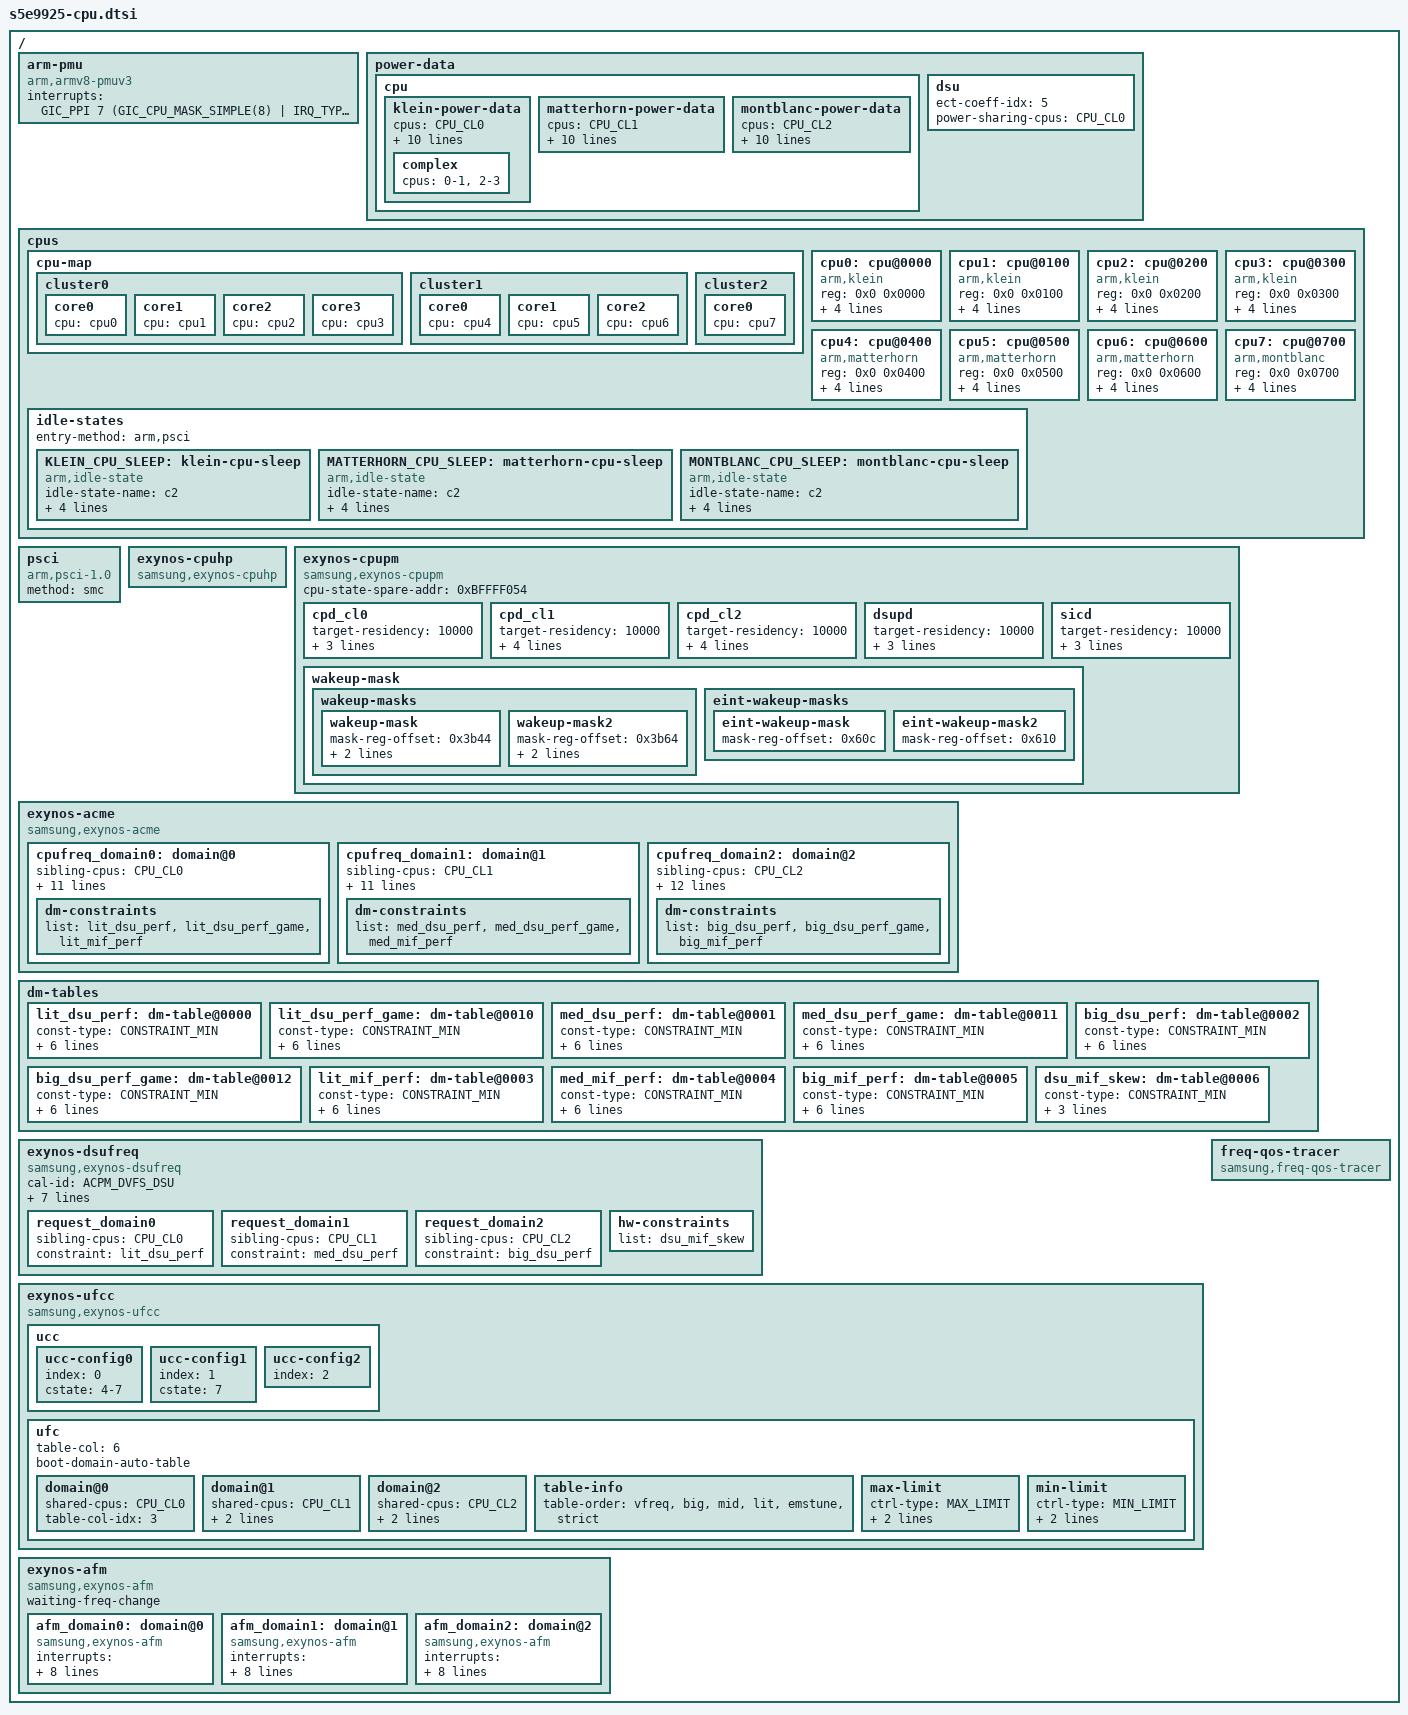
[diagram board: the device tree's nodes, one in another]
/*
 * SAMSUNG S5E9925 SoC CPU device tree source
 *
 * Copyright (c) 2020 Samsung Electronics Co., Ltd.
 *             http://www.samsung.com
 *
 * SAMSUNG EXYNOS9925 SoC device nodes are listed in this file.
 * EXYNOS based board files can include this file and provide
 * values for board specfic bindings.
 *
 * This program is free software; you can redistribute it and/or modify
 * it under the terms of the GNU General Public License version 2 as
 * published by the Free Software Foundation.
 */

#include <dt-bindings/soc/samsung/cpupm.h>

/ {
	arm-pmu {
		compatible = "arm,armv8-pmuv3";
		interrupts = <GIC_PPI 7 (GIC_CPU_MASK_SIMPLE(8) | IRQ_TYPE_LEVEL_HIGH)>;
	};

	#define CPU_CL0	"0-3"
	#define CPU_CL1	"4-6"
	#define CPU_CL2	"7"
	#define CPU_ALL	"0-7"

	power-data {
		#define CPUCL0_DMIPS_PER_MHZ 267
		#define CPUCL1_DMIPS_PER_MHZ 380
		#define CPUCL2_DMIPS_PER_MHZ 488

		#define CPUCL0_DP_COEFF	189
		#define CPUCL1_DP_COEFF	560
		#define CPUCL2_DP_COEFF	765

		#define CPUCL0_SP_COEFF	62
		#define CPUCL1_SP_COEFF	234
		#define CPUCL2_SP_COEFF	537

		cpu {
			klein-power-data {
				/* default power data */
				cpus = CPU_CL0;
				capacity-dmips-mhz = <CPUCL0_DMIPS_PER_MHZ>;
				dynamic-power-coefficient = <CPUCL0_DP_COEFF>;
				static-power-coefficient = <CPUCL0_SP_COEFF>;

				/* precise static power */
				cal-id = <ACPM_DVFS_CPUCL0>;
				ect-param-vt = "DTM_LIT_VOLT_TEMP";
				ect-param-a = "DTM_LIT_ASV";
				tz-name = "LITTLE";

				/* dhrystone to clang conversion ratio */
				dhry-to-clang-dp-ratio = <820>;
				dhry-to-clang-cap-ratio = <538>;

				/* power sharing with dsu */
				power-sharing-dsu;

				complex {
					cpus = "0-1", "2-3";
				};
			};
			matterhorn-power-data {
				/* default power data */
				cpus = CPU_CL1;
				capacity-dmips-mhz = <CPUCL1_DMIPS_PER_MHZ>;
				dynamic-power-coefficient = <CPUCL1_DP_COEFF>;
				static-power-coefficient = <CPUCL1_SP_COEFF>;

				/* precise static power */
				cal-id = <ACPM_DVFS_CPUCL1>;
				ect-param-vt = "DTM_MID_VOLT_TEMP";
				ect-param-a = "DTM_MID_ASV";
				tz-name = "MID";

				/* dhrystone to clang conversion ratio */
				dhry-to-clang-dp-ratio = <820>;
				dhry-to-clang-cap-ratio = <377>;

				/* power sharing cpus */
				power-sharing-cpus = CPU_CL2;
			};
			montblanc-power-data {
				/* default power data */
				cpus = CPU_CL2;
				capacity-dmips-mhz = <CPUCL2_DMIPS_PER_MHZ>;
				dynamic-power-coefficient = <CPUCL2_DP_COEFF>;
				static-power-coefficient = <CPUCL2_SP_COEFF>;

				/* precise static power */
				cal-id = <ACPM_DVFS_CPUCL2>;
				ect-param-vt = "DTM_BIG_VOLT_TEMP";
				ect-param-a = "DTM_BIG_ASV";
				tz-name = "BIG";

				/* dhrystone to clang conversion ratio */
				dhry-to-clang-dp-ratio = <820>;
				dhry-to-clang-cap-ratio = <385>;

				/* power sharing cpus */
				power-sharing-cpus = CPU_CL1;
			};
		};

		dsu {
			/* dynamic power w/ ECT */
			ect-coeff-idx = <5>;

			/* power sharing cpus */
			power-sharing-cpus = CPU_CL0;
		};
	};

	cpus {
		#address-cells = <2>;
		#size-cells = <0>;

		cpu-map {
			cluster0 {
				core0 {
					cpu = <&cpu0>;
				};
				core1 {
					cpu = <&cpu1>;
				};
				core2 {
					cpu = <&cpu2>;
				};
				core3 {
					cpu = <&cpu3>;
				};
			};
			cluster1 {
				core0 {
					cpu = <&cpu4>;
				};
				core1 {
					cpu = <&cpu5>;
				};
				core2 {
					cpu = <&cpu6>;
				};
			};
			cluster2 {
				core0 {
					cpu = <&cpu7>;
				};
			};
		};

		cpu0: cpu@0000 {
			device_type = "cpu";
			compatible = "arm,klein", "arm,armv9";
			reg = <0x0 0x0000>;
			capacity-dmips-mhz = <CPUCL0_DMIPS_PER_MHZ>;
			dynamic-power-coefficient = <CPUCL0_DP_COEFF>;
			enable-method = "psci";
			cpu-idle-states =  <&KLEIN_CPU_SLEEP>;
		};
		cpu1: cpu@0100 {
			device_type = "cpu";
			compatible = "arm,klein", "arm,armv9";
			reg = <0x0 0x0100>;
			capacity-dmips-mhz = <CPUCL0_DMIPS_PER_MHZ>;
			dynamic-power-coefficient = <CPUCL0_DP_COEFF>;
			enable-method = "psci";
			cpu-idle-states =  <&KLEIN_CPU_SLEEP>;
		};
		cpu2: cpu@0200 {
			device_type = "cpu";
			compatible = "arm,klein", "arm,armv9";
			reg = <0x0 0x0200>;
			capacity-dmips-mhz = <CPUCL0_DMIPS_PER_MHZ>;
			dynamic-power-coefficient = <CPUCL0_DP_COEFF>;
			enable-method = "psci";
			cpu-idle-states =  <&KLEIN_CPU_SLEEP>;
		};
		cpu3: cpu@0300 {
			device_type = "cpu";
			compatible = "arm,klein", "arm,armv9";
			reg = <0x0 0x0300>;
			capacity-dmips-mhz = <CPUCL0_DMIPS_PER_MHZ>;
			dynamic-power-coefficient = <CPUCL0_DP_COEFF>;
			enable-method = "psci";
			cpu-idle-states =  <&KLEIN_CPU_SLEEP>;
		};
		cpu4: cpu@0400 {
			device_type = "cpu";
			compatible = "arm,matterhorn", "arm,armv9";
			reg = <0x0 0x0400>;
			capacity-dmips-mhz = <CPUCL1_DMIPS_PER_MHZ>;
			dynamic-power-coefficient = <CPUCL1_DP_COEFF>;
			enable-method = "psci";
			cpu-idle-states =  <&MATTERHORN_CPU_SLEEP>;
		};
		cpu5: cpu@0500 {
			device_type = "cpu";
			compatible = "arm,matterhorn", "arm,armv9";
			reg = <0x0 0x0500>;
			capacity-dmips-mhz = <CPUCL1_DMIPS_PER_MHZ>;
			dynamic-power-coefficient = <CPUCL1_DP_COEFF>;
			enable-method = "psci";
			cpu-idle-states =  <&MATTERHORN_CPU_SLEEP>;
		};
		cpu6: cpu@0600 {
			device_type = "cpu";
			compatible = "arm,matterhorn", "arm,armv9";
			reg = <0x0 0x0600>;
			capacity-dmips-mhz = <CPUCL1_DMIPS_PER_MHZ>;
			dynamic-power-coefficient = <CPUCL1_DP_COEFF>;
			enable-method = "psci";
			cpu-idle-states =  <&MATTERHORN_CPU_SLEEP>;
		};
		cpu7: cpu@0700 {
			device_type = "cpu";
			compatible = "arm,montblanc", "arm,armv9";
			reg = <0x0 0x0700>;
			capacity-dmips-mhz = <CPUCL2_DMIPS_PER_MHZ>;
			dynamic-power-coefficient = <CPUCL2_DP_COEFF>;
			enable-method = "psci";
			cpu-idle-states =  <&MONTBLANC_CPU_SLEEP>;
		};

		idle-states {
			entry-method = "arm,psci";

			KLEIN_CPU_SLEEP: klein-cpu-sleep {
				idle-state-name = "c2";
				compatible = "arm,idle-state";
				arm,psci-suspend-param = <0x0010000>;
				entry-latency-us = <70>;
				exit-latency-us = <160>;
				min-residency-us = <2000>;
				status = "okay";
			};

			MATTERHORN_CPU_SLEEP: matterhorn-cpu-sleep {
				idle-state-name = "c2";
				compatible = "arm,idle-state";
				arm,psci-suspend-param = <0x0010000>;
				entry-latency-us = <150>;
				exit-latency-us = <190>;
				min-residency-us = <2500>;
				status = "okay";
			};

			MONTBLANC_CPU_SLEEP: montblanc-cpu-sleep {
				idle-state-name = "c2";
				compatible = "arm,idle-state";
				arm,psci-suspend-param = <0x0010000>;
				entry-latency-us = <235>;
				exit-latency-us = <220>;
				min-residency-us = <3500>;
				status = "okay";
			};

		};

	};

	psci {
		compatible = "arm,psci-1.0";
		method = "smc";
	};

	exynos-cpuhp {
		compatible = "samsung,exynos-cpuhp";
		status = "okay";
	};

	exynos-cpupm {
		compatible = "samsung,exynos-cpupm";
		status = "okay";
		cpu-state-spare-addr = <0xBFFFF054>;

		cpd_cl0 {
			device_type ="cpupm";
			target-residency = <10000>;
			type = <POWERMODE_TYPE_CLUSTER>;
			cal-id = <0>;
			siblings = CPU_CL0;
		};

		cpd_cl1 {
			device_type = "cpupm";
			target-residency = <10000>;
			type = <POWERMODE_TYPE_CLUSTER>;
			cal-id = <1>;
			siblings = CPU_CL1;
			entry-allowed = CPU_CL1;
		};

		cpd_cl2 {
			device_type = "cpupm";
			target-residency = <10000>;
			type = <POWERMODE_TYPE_CLUSTER>;
			cal-id = <2>;
			siblings = CPU_CL2;
			entry-allowed = CPU_CL2;
		};

		dsupd {
			device_type = "cpupm";
			target-residency = <10000>;
			type = <POWERMODE_TYPE_DSU>;
			siblings = CPU_ALL;
			entry-allowed = CPU_ALL;
		};

		sicd {
			device_type = "cpupm";
			target-residency = <10000>;
			type = <POWERMODE_TYPE_SYSTEM>;
			siblings = CPU_ALL;
			entry-allowed = CPU_ALL;
		};

		wakeup-mask {
			wakeup-masks {
				wakeup-mask {
					mask-reg-offset = <0x3b44>;
					stat-reg-offset = <0x3b50>;
					mask = <0xff000000>;
				};
				wakeup-mask2 {
					mask-reg-offset = <0x3b64>;
					stat-reg-offset = <0x3b54>;
					mask = <0x00>;
				};
			};

			eint-wakeup-masks {
				eint-wakeup-mask {
					mask-reg-offset = <0x60c>;
				};
				eint-wakeup-mask2 {
					mask-reg-offset = <0x610>;
				};
			};
		};
	};

	exynos-acme {
		compatible = "samsung,exynos-acme";
		status = "okay";

		cpufreq_domain0: domain@0 {
			sibling-cpus = CPU_CL0;
			cal-id = <ACPM_DVFS_CPUCL0>;
			dm-type = <DM_CPU_CL0>;
			dss-type = <ESS_FLAG_CPU_CL0>;

			max-freq = <1728000>;
			min-freq = <400000>;

			fast-switch;
			thread-run-on = "0-5";

			#cooling-cells = <2>; /* min followed by max */
			ect-coeff-index = <2>;
			tz-cooling-name = "LITTLE";

			freq-table = <  400000
					576000
					672000
					768000
					864000
					960000
					1056000
					1152000
					1248000
					1344000
					1440000
					1536000
					1632000
					1728000 >;

			dm-constraints {
				list = <&lit_dsu_perf>,
					<&lit_dsu_perf_game>,
					<&lit_mif_perf>;
			};
		};

		cpufreq_domain1: domain@1 {
			sibling-cpus = CPU_CL1;
			cal-id = <ACPM_DVFS_CPUCL1>;
			dm-type = <DM_CPU_CL1>;
			dss-type = <ESS_FLAG_CPU_CL1>;

			max-freq = <2515000>;
			min-freq = <576000>;

			fast-switch;
			thread-run-on = "0-5";

			#cooling-cells = <2>; /* min followed by max */
			ect-coeff-index = <1>;
			tz-cooling-name = "MID";

			freq-table = <  576000
					672000
					768000
					864000
					960000
					1056000
					1152000
					1248000
					1344000
					1440000
					1536000
					1632000
					1728000
					1824000
					1920000
					2016000
					2112000
					2208000
					2304000
					2400000
					2515000 >;

			dm-constraints {
				list = <&med_dsu_perf>,
					<&med_dsu_perf_game>,
					<&med_mif_perf>;
			};
		};

		cpufreq_domain2: domain@2 {
			sibling-cpus = CPU_CL2;
			cal-id = <ACPM_DVFS_CPUCL2>;
			dm-type = <DM_CPU_CL2>;
			dss-type = <ESS_FLAG_CPU_CL2>;

			max-freq = <2803000>;
			min-freq = <576000>;

			fast-switch;
			thread-run-on = "0-5";

			pm_qos-booting = <2611000>;

			#cooling-cells = <2>; /* min followed by max */
			ect-coeff-index = <0>;
			tz-cooling-name = "BIG";

			freq-table = <  576000
					672000
					768000
					864000
					960000
					1056000
					1152000
					1248000
					1344000
					1440000
					1536000
					1632000
					1728000
					1824000
					1920000
					2016000
					2112000
					2208000
					2304000
					2400000
					2515000
					2611000
					2707000
					2803000 >;

			dm-constraints {
				list = <&big_dsu_perf>,
					<&big_dsu_perf_game>,
					<&big_mif_perf>;
			};
		};
	};

	dm-tables {
		lit_dsu_perf: dm-table@0000 {
			const-type = <CONSTRAINT_MIN>;
			dm-slave = <DM_DSU>;
			master-cal-id = <ACPM_DVFS_CPUCL0>;
			slave-cal-id = <ACPM_DVFS_DSU>;
			multi-table;

				/* CPU	  DSU */
			table = < 400000  240000
				  576000  384000
				  672000  432000
				  768000  528000
				  864000  576000
				  960000  624000
				  1056000 720000
				  1152000 768000
				  1248000 816000
				  1344000 912000
				  1440000 960000
				  1536000 1008000
				  1632000 1104000
				  1728000 1152000 >;
		};
		lit_dsu_perf_game: dm-table@0010 {
			const-type = <CONSTRAINT_MIN>;
			dm-slave = <DM_DSU>;
			master-cal-id = <ACPM_DVFS_CPUCL0>;
			slave-cal-id = <ACPM_DVFS_DSU>;
			multi-table;

				/* CPU	  DSU */
			table = < 400000  200000
				  576000  288000
				  672000  336000
				  768000  384000
				  864000  432000
				  960000  480000
				  1056000 528000
				  1152000 576000
				  1248000 624000
				  1344000 672000
				  1440000 720000
				  1536000 768000
				  1632000 1104000
				  1728000 1152000 >;
		};
		med_dsu_perf: dm-table@0001 {
			const-type = <CONSTRAINT_MIN>;
			dm-slave = <DM_DSU>;
			master-cal-id = <ACPM_DVFS_CPUCL1>;
			slave-cal-id = <ACPM_DVFS_DSU>;
			multi-table;

				/* CPU	  DSU */
			table = < 576000  267000
				  672000  432000
				  768000  528000
				  864000  576000
				  960000  624000
				  1056000 720000
				  1152000 768000
				  1248000 816000
				  1344000 864000
				  1440000 960000
				  1536000 1008000
				  1632000 1104000
				  1728000 1152000
				  1824000 1200000
				  1920000 1248000
				  2016000 1344000
				  2112000 1392000
				  2208000 1440000
				  2304000 1536000
				  2400000 1584000
				  2515000 1728000 >;
		};
		med_dsu_perf_game: dm-table@0011 {
			const-type = <CONSTRAINT_MIN>;
			dm-slave = <DM_DSU>;
			master-cal-id = <ACPM_DVFS_CPUCL1>;
			slave-cal-id = <ACPM_DVFS_DSU>;
			multi-table;

				/* CPU	  DSU */
			table = < 576000  288000
				  672000  336000
				  768000  384000
				  864000  432000
				  960000  480000
				  1056000 528000
				  1152000 576000
				  1248000 624000
				  1344000 672000
				  1440000 720000
				  1536000 768000
				  1632000 816000
				  1728000 864000
				  1824000 1200000
				  1920000 1248000
				  2016000 1344000
				  2112000 1392000
				  2208000 1440000
				  2304000 1536000
				  2400000 1584000
				  2515000 1632000 >;
		};
		big_dsu_perf: dm-table@0002 {
			const-type = <CONSTRAINT_MIN>;
			dm-slave = <DM_DSU>;
			master-cal-id = <ACPM_DVFS_CPUCL2>;
			slave-cal-id = <ACPM_DVFS_DSU>;
			multi-table;

				/* CPU	  DSU */
			table = < 576000  267000
				  672000  432000
				  768000  528000
				  864000  576000
				  960000  624000
				  1056000 720000
				  1152000 768000
				  1248000 816000
				  1344000 912000
				  1440000 960000
				  1536000 1008000
				  1632000 1104000
				  1728000 1152000
				  1824000 1200000
				  1920000 1248000
				  2016000 1344000
				  2112000 1392000
				  2208000 1440000
				  2304000 1536000
				  2400000 1584000
				  2515000 1728000
				  2611000 1728000
				  2707000 1728000
				  2803000 1728000 >;
		};
		big_dsu_perf_game: dm-table@0012 {
			const-type = <CONSTRAINT_MIN>;
			dm-slave = <DM_DSU>;
			master-cal-id = <ACPM_DVFS_CPUCL2>;
			slave-cal-id = <ACPM_DVFS_DSU>;
			multi-table;

				/* CPU	  DSU */
			table = < 576000  288000
				  672000  336000
				  768000  384000
				  864000  432000
				  960000  480000
				  1056000 528000
				  1152000 576000
				  1248000 624000
				  1344000 672000
				  1440000 720000
				  1536000 768000
				  1632000 816000
				  1728000 864000
				  1824000 1200000
				  1920000 1248000
				  2016000 1344000
				  2112000 1392000
				  2208000 1440000
				  2304000 1536000
				  2400000 1584000
				  2515000 1632000
				  2611000 1632000
				  2707000 1632000
				  2803000 1632000 >;
		};
		lit_mif_perf: dm-table@0003 {
			const-type = <CONSTRAINT_MIN>;
			dm-slave = <DM_MIF>;
			master-cal-id = <ACPM_DVFS_CPUCL0>;
			slave-cal-id = <ACPM_DVFS_MIF>;
			dynamic-disable;

				/* CPU	   MIF */
			table = < 400000   0
				  576000   0
				  672000   0
				  768000   0
				  864000   0
				  960000   0
				  1056000  0
				  1152000  0
				  1248000  0
				  1344000  0
				  1440000  0
				  1536000  0
				  1632000  0
				  1728000  0 >;
		};
		med_mif_perf: dm-table@0004 {
			const-type = <CONSTRAINT_MIN>;
			dm-slave = <DM_MIF>;
			master-cal-id = <ACPM_DVFS_CPUCL1>;
			slave-cal-id = <ACPM_DVFS_MIF>;
			dynamic-disable;

				/* CPU	   MIF */
			table = < 576000   0
				  672000   0
				  768000   0
				  864000   0
				  960000   0
				  1056000  0
				  1152000  0
				  1248000  0
				  1344000  0
				  1440000  0
				  1536000  0
				  1632000  0
				  1728000  0
				  1824000  0
				  1920000  0
				  2016000  2288000
				  2112000  2288000
				  2208000  2288000
				  2304000  2535000
				  2400000  2730000
				  2515000  3172000 >;
		};
		big_mif_perf: dm-table@0005 {
			const-type = <CONSTRAINT_MIN>;
			dm-slave = <DM_MIF>;
			master-cal-id = <ACPM_DVFS_CPUCL2>;
			slave-cal-id = <ACPM_DVFS_MIF>;
			dynamic-disable;

				/* CPU	   MIF */
			table = <
				  576000   0
				  672000   0
				  768000   0
				  864000   0
				  960000   0
				  1056000  0
				  1152000  0
				  1248000  0
				  1344000  0
				  1440000  0
				  1536000  0
				  1632000  0
				  1728000  0
				  1824000  0
				  1920000  0
				  2016000  2288000
				  2112000  2288000
				  2208000  2288000
				  2304000  2535000
				  2400000  2535000
				  2515000  2730000
				  2611000  3172000
				  2707000  3172000
				  2803000  3172000 >;
		};
		dsu_mif_skew: dm-table@0006 {
			const-type = <CONSTRAINT_MIN>;
			dm-slave = <DM_MIF>;
			ect-name = "DSU_MIF";
			guidance;
		};
	};

	exynos-dsufreq {
		compatible = "samsung,exynos-dsufreq";
		status = "okay";

		cal-id = <ACPM_DVFS_DSU>;
		dm-type = <DM_DSU>;
		dss-type = <ESS_FLAG_DSU>;
		max-freq = <1728000>;
		min-freq = <96000>;
		init-with-dt = <1>;

		table = < 96000
			144000
			192000
			240000
			288000
			336000
			384000
			432000
			480000
			528000
			576000
			624000
			672000
			720000
			768000
			816000
			864000
			912000
			960000
			1008000
			1056000
			1104000
			1152000
			1200000
			1248000
			1296000
			1344000
			1392000
			1440000
			1488000
			1536000
			1584000
			1632000
			1728000 >;

		request_domain0 {
			sibling-cpus = CPU_CL0;
			constraint = <&lit_dsu_perf>;
		};
		request_domain1 {
			sibling-cpus = CPU_CL1;
			constraint = <&med_dsu_perf>;
		};
		request_domain2 {
			sibling-cpus = CPU_CL2;
			constraint = <&big_dsu_perf>;
		};
		hw-constraints {
			list = <&dsu_mif_skew>;
		};
	};

	exynos-ufcc {
		compatible = "samsung,exynos-ufcc";
		status = "okay";

		ucc {
			ucc-config0 {
				index = <0>;
				cstate = "4-7";
			};
			ucc-config1 {
				index = <1>;
				cstate = "7";
			};
			ucc-config2 {
				index = <2>;
			};
		};

		ufc {
			/* Ctrl Type */
			#define MIN_LIMIT		0
			#define MIN_LIMIT_WO_BOOST	1
			#define MAX_LIMIT		2

			table-col = <6>;
			boot-domain-auto-table;

			domain@0 {
				device_type = "ufc-domain";
				shared-cpus = CPU_CL0;
				table-col-idx = <3>;
			};
			domain@1 {
				device_type = "ufc-domain";
				shared-cpus = CPU_CL1;
				table-col-idx = <2>;
				allow-disable-cpus;
			};
			domain@2 {
				device_type = "ufc-domain";
				shared-cpus = CPU_CL2;
				table-col-idx = <1>;
				allow-disable-cpus;
			};

			table-info {
				table-order = "vfreq",
					"big",
					"mid",
					"lit",
					"emstune",
					"strict";
			};

			max-limit {
				device_type = "ufc-table";
				ctrl-type = <MAX_LIMIT>;

				table = < 2803000 2803000 2515000 1728000 0 0
					  2707000 2707000 2515000 1728000 0 0
					  2611000 2611000 2515000 1536000 0 0
					  2515000 2515000 2515000 1536000 0 0
					  2400000 2400000 2400000 1536000 0 0
					  2304000 2304000 2304000 1536000 0 0
					  2208000 2208000 2208000 1536000 0 0
					  2112000 2112000 2112000 1536000 0 0
					  2016000 2016000 2016000 1536000 0 0
					  1920000 1920000 1920000 1344000 0 0
					  1824000 1824000 1824000 1344000 0 0
					  1728000 1728000 1728000 1344000 0 0
					  1632000 1632000 1632000 1344000 0 0
					  1536000 1536000 1536000 1344000 0 0
					  1440000 1440000 1440000 1344000 0 0
					  1344000 1344000 1344000 1344000 0 0
					  1248000 1248000 1248000 1344000 0 0
					  1152000 1152000 1152000 1344000 0 0
					  1056000 1056000 1056000 1344000 0 0
					   960000  960000  960000 1344000 0 0
					   864000  864000  864000 1344000 0 0
 					   768000  768000  768000 1344000 0 0
					   672000  672000  672000 1344000 0 0
					   576000  576000  576000 1344000 0 0 >;
					  /* fill little freq automatically */
			};

			min-limit {
				device_type = "ufc-table";
				ctrl-type = <MIN_LIMIT>;

				table = < 2803000 2803000 2515000 1728000 2 1
					  2707000 2707000 2515000 1728000 2 1
					  2611000 2611000 2515000 1728000 2 1
					  2515000 2515000 2515000 1728000 2 1
					  2400000 2400000 2400000 1152000 2 1
					  2304000 2304000 2304000 1152000 2 1
					  2208000 2208000 2208000 1152000 2 1
					  2112000 2112000 2112000 1152000 2 1
					  2016000 2016000 2016000 1152000 2 1
					  1920000 1920000 1920000 1152000 2 1
					  1824000 1824000 1824000 1152000 1 1
 					  1728000 1728000 1728000  960000 1 1
					  1632000 1632000 1632000  960000 1 1
 					  1536000 1536000 1536000  960000 1 1
					  1440000 1440000 1440000  960000 1 1
 					  1344000 1344000 1344000  960000 1 1
					  1248000 1248000 1248000  960000 1 1
 					  1152000 1152000 1152000  960000 1 1
					  1056000 1056000 1056000  960000 1 1
 					   960000  960000  960000  768000 1 1
					   864000  864000  864000  768000 1 1
 					   768000  768000  768000  768000 0 1
					   672000  672000  672000  768000 0 1
					   576000  576000  576000  768000 0 1 >;
					  /* fill little freq automatically */
			};
		};
	};

	freq-qos-tracer {
		compatible = "samsung,freq-qos-tracer";
		status = "okay";
	};

	exynos-afm {
		#define MAIN_PMIC 1
		#define SUB_PMIC  2
		compatible = "samsung,exynos-afm";
		status = "okay";
		waiting-freq-change;

		afm_domain0: domain@0 {
			device_type = "afm-domain";
			compatible = "samsung,exynos-afm";
			interrupts = <GIC_SPI INTREQ__OCP_REATOR_CPUCL0_0 IRQ_TYPE_LEVEL_HIGH>;
			sibling-cpus = "0-3";
			interrupt-src = <MAIN_PMIC>;
			s2mps-afm-offset = <0x74>;
			htu-base-addr = <0x1D080000>;
			down-step = <1>;
			max-freq-wo-afm = <2002000>;
			release-duration = <15>;
		};
		afm_domain1: domain@1 {
			device_type = "afm-domain";
			compatible = "samsung,exynos-afm";
			interrupts = <GIC_SPI INTREQ__OCP_REATOR_CPUCL0_1 IRQ_TYPE_LEVEL_HIGH>;
			sibling-cpus = "4-6";
			interrupt-src = <MAIN_PMIC>;
			s2mps-afm-offset = <0x80>;
			htu-base-addr = <0x1D090000>;
			down-step = <1>;
			max-freq-wo-afm = <2002000>;
			release-duration = <15>;
		};
		afm_domain2: domain@2 {
			device_type = "afm-domain";
			compatible = "samsung,exynos-afm";
			interrupts = <GIC_SPI INTREQ__OCP_REATOR_CPUCL0_2 IRQ_TYPE_LEVEL_HIGH>;
			sibling-cpus = "7";
			interrupt-src = <MAIN_PMIC>;
			s2mps-afm-offset = <0x80>;
			htu-base-addr = <0x1D0A0000>;
			down-step = <1>;
			max-freq-wo-afm = <2002000>;
			release-duration = <15>;
		};
	};
};
